# ESP32-P4 register map
Vendor: ESPRESSIF SYSTEMS (SHANGHAI) CO., LTD.; Series: ESP32 P-Series; File version: 3
CPU: RV32IMAFC r0p0, little endian, no MPU, FPU, 0 interrupt priority bits
Address unit: 32 bits
Registers are 32-bit, read-write, reset 0x0 unless marked. A register's access mark holds for its fields unless they carry their own. Offsets are from the block's base; [hi:lo] are bit positions; {n}, {i} and the like mark numbered series; 'fields as' and 'values as' point back to an identical list.

## IOMUX_MSPI_PIN — IOMUX_MSPI_PIN Peripheral
Base 0x500E1200
0x00 CLK_EN0 reset 0x1 — apb registers auto clock gating reg
  [0] REG_CLK_EN — 1: auto clock gating on 0: auto clock gating off
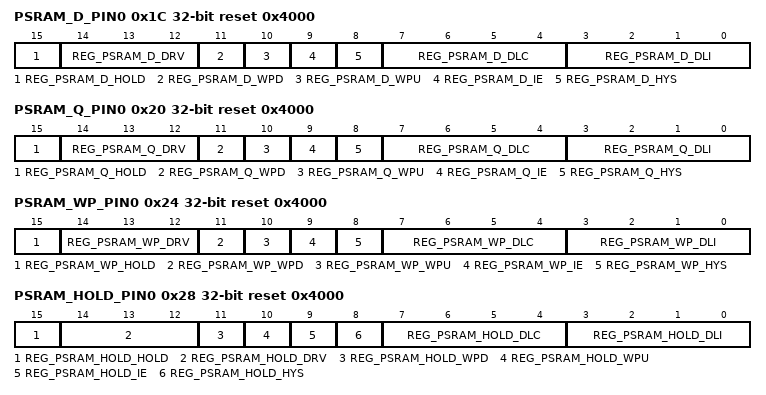
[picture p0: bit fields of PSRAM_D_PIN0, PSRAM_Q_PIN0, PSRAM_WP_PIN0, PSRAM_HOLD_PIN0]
0x1C PSRAM_D_PIN0 reset 0x4000 — IOMUX_MSPI_PIN_PSRAM_D_PIN0_REG
  [15] REG_PSRAM_D_HOLD — psram d hold
  [14:12] REG_PSRAM_D_DRV — psram d drv
  [11] REG_PSRAM_D_WPD — psram d wpd
  [10] REG_PSRAM_D_WPU — psram d wpu
  [9] REG_PSRAM_D_IE — Reserved
  [8] REG_PSRAM_D_HYS — psram d sl
  [7:4] REG_PSRAM_D_DLC — psram d dlc
  [3:0] REG_PSRAM_D_DLI — psram d dli
0x20 PSRAM_Q_PIN0 reset 0x4000 — IOMUX_MSPI_PIN_PSRAM_D_PIN0_REG
  [15] REG_PSRAM_Q_HOLD — psram q hold
  [14:12] REG_PSRAM_Q_DRV — psram q drv
  [11] REG_PSRAM_Q_WPD — psram q wpd
  [10] REG_PSRAM_Q_WPU — psram q wpu
  [9] REG_PSRAM_Q_IE — Reserved
  [8] REG_PSRAM_Q_HYS — psram q sl
  [7:4] REG_PSRAM_Q_DLC — psram q dlc
  [3:0] REG_PSRAM_Q_DLI — psram q dli
0x24 PSRAM_WP_PIN0 reset 0x4000 — IOMUX_MSPI_PIN_PSRAM_D_PIN0_REG
  [15] REG_PSRAM_WP_HOLD — psram wp hold
  [14:12] REG_PSRAM_WP_DRV — psram wp drv
  [11] REG_PSRAM_WP_WPD — psram wp wpd
  [10] REG_PSRAM_WP_WPU — psram wp wpu
  [9] REG_PSRAM_WP_IE — Reserved
  [8] REG_PSRAM_WP_HYS — psram wp sl
  [7:4] REG_PSRAM_WP_DLC — psram wp dlc
  [3:0] REG_PSRAM_WP_DLI — psram wp dli
0x28 PSRAM_HOLD_PIN0 reset 0x4000 — IOMUX_MSPI_PIN_PSRAM_D_PIN0_REG
  [15] REG_PSRAM_HOLD_HOLD — psram hold hold
  [14:12] REG_PSRAM_HOLD_DRV — psram hold drv
  [11] REG_PSRAM_HOLD_WPD — psram hold wpd
  [10] REG_PSRAM_HOLD_WPU — psram hold wpu
  [9] REG_PSRAM_HOLD_IE — Reserved
  [8] REG_PSRAM_HOLD_HYS — psram hold sl
  [7:4] REG_PSRAM_HOLD_DLC — psram hold dlc
  [3:0] REG_PSRAM_HOLD_DLI — psram hold dli
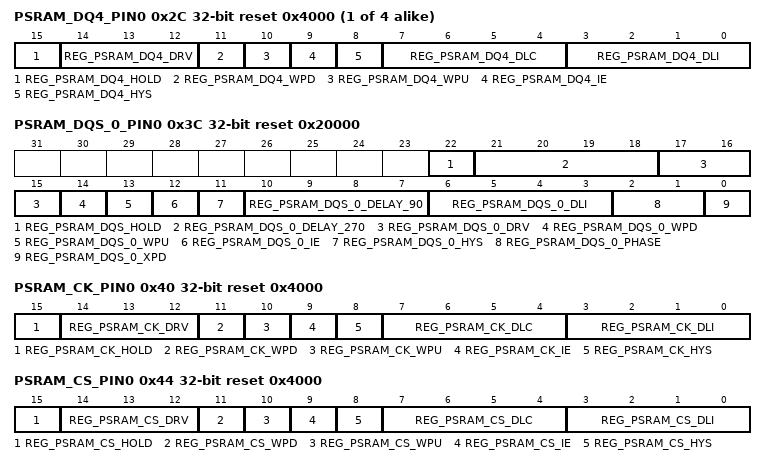
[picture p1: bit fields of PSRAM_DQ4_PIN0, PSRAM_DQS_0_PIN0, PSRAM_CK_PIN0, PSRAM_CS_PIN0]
{0x1C+4i} PSRAM_DQ{i}_PIN0 reset 0x4000 (i=4..7) — IOMUX_MSPI_PIN_PSRAM_D_PIN0_REG
  [15] REG_PSRAM_DQ{i}_HOLD — psram dq{i} hold
  [14:12] REG_PSRAM_DQ{i}_DRV — psram dq{i} drv
  [11] REG_PSRAM_DQ{i}_WPD — psram dq{i} wpd
  [10] REG_PSRAM_DQ{i}_WPU — psram dq{i} wpu
  [9] REG_PSRAM_DQ{i}_IE — Reserved
  [8] REG_PSRAM_DQ{i}_HYS — psram dq{i} sl
  [7:4] REG_PSRAM_DQ{i}_DLC — psram dq{i} dlc
  [3:0] REG_PSRAM_DQ{i}_DLI — psram dq{i} dli
0x3C PSRAM_DQS_0_PIN0 reset 0x20000 — IOMUX_MSPI_PIN_PSRAM_D_PIN0_REG
  [22] REG_PSRAM_DQS_HOLD — psram dqs hold
  [21:18] REG_PSRAM_DQS_0_DELAY_270 — psram dqs0 delay 270
  [17:15] REG_PSRAM_DQS_0_DRV — psram dqs0 drv
  [14] REG_PSRAM_DQS_0_WPD — psram dqs0 wpd
  [13] REG_PSRAM_DQS_0_WPU — psram dqs0 wpu
  [12] REG_PSRAM_DQS_0_IE — Reserved
  [11] REG_PSRAM_DQS_0_HYS — psram dqs0 sl
  [10:7] REG_PSRAM_DQS_0_DELAY_90 — psram dqs0 delay 90
  [6:3] REG_PSRAM_DQS_0_DLI — psram dqs0 dli
  [2:1] REG_PSRAM_DQS_0_PHASE — psram dqs0 phase
  [0] REG_PSRAM_DQS_0_XPD — psram xpd dqs0
0x40 PSRAM_CK_PIN0 reset 0x4000 — IOMUX_MSPI_PIN_PSRAM_D_PIN0_REG
  [15] REG_PSRAM_CK_HOLD — psram ck hold
  [14:12] REG_PSRAM_CK_DRV — psram ck drv
  [11] REG_PSRAM_CK_WPD — psram ck wpd
  [10] REG_PSRAM_CK_WPU — psram ck wpu
  [9] REG_PSRAM_CK_IE — Reserved
  [8] REG_PSRAM_CK_HYS — psram ck sl
  [7:4] REG_PSRAM_CK_DLC — psram ck dlc
  [3:0] REG_PSRAM_CK_DLI — psram ck dli
0x44 PSRAM_CS_PIN0 reset 0x4000 — IOMUX_MSPI_PIN_PSRAM_D_PIN0_REG
  [15] REG_PSRAM_CS_HOLD — psram cs hold
  [14:12] REG_PSRAM_CS_DRV — psram cs drv
  [11] REG_PSRAM_CS_WPD — psram cs wpd
  [10] REG_PSRAM_CS_WPU — psram cs wpu
  [9] REG_PSRAM_CS_IE — Reserved
  [8] REG_PSRAM_CS_HYS — psram cs sl
  [7:4] REG_PSRAM_CS_DLC — psram cs dlc
  [3:0] REG_PSRAM_CS_DLI — psram cs dli
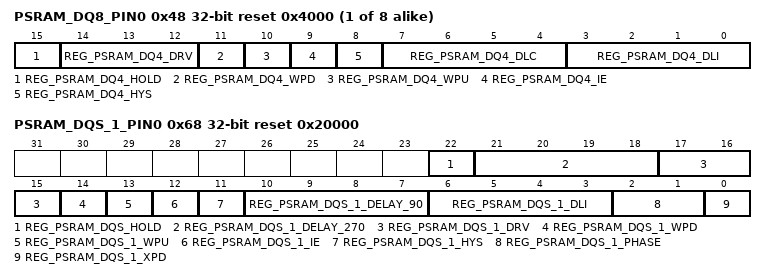
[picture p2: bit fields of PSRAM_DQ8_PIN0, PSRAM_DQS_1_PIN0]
{0x28+4i} PSRAM_DQ{i}_PIN0 reset 0x4000 (i=8..15) — IOMUX_MSPI_PIN_PSRAM_D_PIN0_REG
  fields as PSRAM_DQ4_PIN0
0x68 PSRAM_DQS_1_PIN0 reset 0x20000 — IOMUX_MSPI_PIN_PSRAM_D_PIN0_REG
  [22] REG_PSRAM_DQS_HOLD — psram dqs hold
  [21:18] REG_PSRAM_DQS_1_DELAY_270 — psram dqs1 delay 270
  [17:15] REG_PSRAM_DQS_1_DRV — psram dqs1 drv
  [14] REG_PSRAM_DQS_1_WPD — psram dqs1 wpd
  [13] REG_PSRAM_DQS_1_WPU — psram dqs1 wpu
  [12] REG_PSRAM_DQS_1_IE — Reserved
  [11] REG_PSRAM_DQS_1_HYS — psram dqs1 sl
  [10:7] REG_PSRAM_DQS_1_DELAY_90 — psram dqs1 delay 90
  [6:3] REG_PSRAM_DQS_1_DLI — psram dqs1 dli
  [2:1] REG_PSRAM_DQS_1_PHASE — psram dqs1 phase
  [0] REG_PSRAM_DQS_1_XPD — psram xpd dqs1
